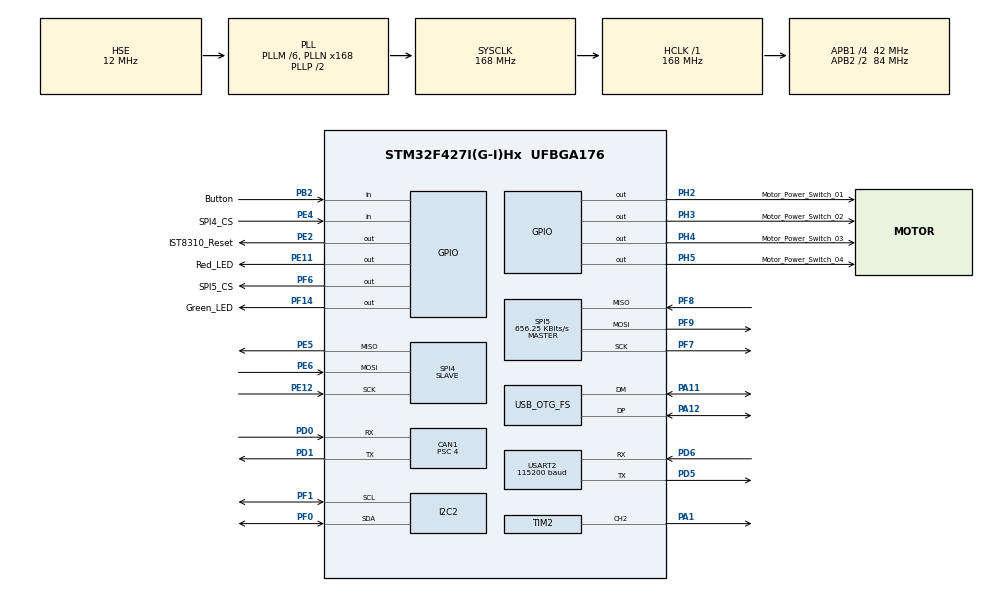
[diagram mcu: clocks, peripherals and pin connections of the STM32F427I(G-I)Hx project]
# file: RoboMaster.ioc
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Mcu.Family=STM32F4
USB_DEVICE.CLASS_NAME_FS=CDC
RCC.CortexFreq_Value=168000000
SPI4.VirtualType=VM_SLAVE
PE11.GPIO_Label=Red_LED
SPI4.Direction=SPI_DIRECTION_2LINES
PA11.Mode=Device_Only
USB_DEVICE.VirtualMode-CDC_FS=Cdc
PH5.GPIO_Label=Motor_Power_Switch_04
TIM2.Channel-PWM\ Generation2\ CH2=TIM_CHANNEL_2
PF6.GPIO_Label=SPI5_CS
RCC.SYSCLKSource=RCC_SYSCLKSOURCE_PLLCLK
ProjectManager.StackSize=0x400
VP_FREERTOS_VS_CMSIS_V2.Mode=CMSIS_V2
PA12.Signal=USB_OTG_FS_DP
PH5.Signal=GPIO_Output
SPI4.Mode=SPI_MODE_SLAVE
PF7.Signal=SPI5_SCK
NVIC.CAN1_TX_IRQn=true\:5\:0\:false\:false\:true\:true\:true\:true
PH0/OSC_IN.Mode=HSE-External-Oscillator
RCC.HCLKFreq_Value=168000000
RCC.APB2TimFreq_Value=168000000
PB2/BOOT1.GPIO_Label=Button
PH1/OSC_OUT.Signal=RCC_OSC_OUT
PD0.Signal=CAN1_RX
PE5.Signal=SPI4_MISO
RCC.AHBFreq_Value=168000000
PD5.Mode=Asynchronous
RCC.HSE_VALUE=12000000
PF9.Mode=Full_Duplex_Master
PE4.GPIO_Label=SPI4_CS
PE2.Signal=GPIO_Output
PF8.Mode=Full_Duplex_Master
PH1/OSC_OUT.Mode=HSE-External-Oscillator
PE4.Signal=GPIO_Input
CAN1.Prescaler=4
Mcu.Package=UFBGA176
SPI5.BaudRatePrescaler=SPI_BAUDRATEPRESCALER_128
TIM2.Prescaler=168
NVIC.TimeBase=TIM8_UP_TIM13_IRQn
USART2.VirtualMode=VM_ASYNC
NVIC.OTG_FS_IRQn=true\:5\:0\:false\:false\:true\:true\:true\:true
NVIC.TimeBaseIP=TIM13
USB_OTG_FS.VirtualMode=Device_Only
PF8.Signal=SPI5_MISO
PH3.GPIO_Label=Motor_Power_Switch_02
SPI5.CalculateBaudRate=656.25 KBits/s
PH2.Signal=GPIO_Output
RCC.APB2CLKDivider=RCC_HCLK_DIV2
PF14.Signal=GPIO_Output
RCC.APB1TimFreq_Value=84000000
PF0.Signal=I2C2_SDA
PD6.Signal=USART2_RX
CAN1.CalculateTimeBit=1142.85
PE2.GPIO_Label=IST8310_Reset
SPI5.VirtualType=VM_MASTER
CAN1.CalculateTimeQuantum=95.23809523809524
PE12.Mode=Full_Duplex_Slave
FREERTOS.Tasks01=DefaultTask,24,1024,StartDefaultTask,Default,NULL,Dynamic,NULL,NULL;BlinkLEDTask,8,128,StartBlinkLEDTask,Default,NULL,Static,myTask02Buffer,myTask02ControlBlock;UpdatePIDTask,32,512,StartUpdatePIDTask,Default,NULL,Static,myTask03Buffer,myTask03ControlBlock;PrintInfo,16,512,StartPrintInfo,Default,NULL,Static,printInfoBuffer,printInfoControlBlock;ActuatorsTask,24,2048,StartActuatorsTask,Default,NULL,Static,ActuatorsTaskBuffer,ActuatorsTaskControlBlock;SensorsTask,24,2048,StartSensorsTask,Default,NULL,Static,SensorsTaskBuffer,SensorsTaskControlBlock;UpdateIMUTask,32,1024,StartUpdateIMUTask,Default,NULL,Static,UpdateIMUTaskBuffer,UpdateIMUTaskControlBlock
USB_DEVICE.VirtualModeFS=Cdc_FS
CAN1.CalculateBaudRate=875000
PD1.Signal=CAN1_TX
PD5.Signal=USART2_TX
PF14.GPIO_Label=Green_LED
RCC.APB1CLKDivider=RCC_HCLK_DIV4
PD6.Mode=Asynchronous
NVIC.USART2_IRQn=true\:5\:0\:false\:false\:true\:true\:true\:true
SPI5.Mode=SPI_MODE_MASTER
USART2.BaudRate=115200
PF7.Mode=Full_Duplex_Master
PF1.Mode=I2C
SH.S_TIM2_CH2.0=TIM2_CH2,PWM Generation2 CH2
PB2/BOOT1.Signal=GPIO_Input
PH4.Signal=GPIO_Output
CAN1.BS2=CAN_BS2_2TQ
PF6.Signal=GPIO_Output
CAN1.BS1=CAN_BS1_9TQ
ProjectManager.TargetToolchain=STM32CubeIDE
VP_USB_DEVICE_VS_USB_DEVICE_CDC_FS.Mode=CDC_FS
PE11.Signal=GPIO_Output
RCC.LSE_VALUE=32768
PA1.Signal=S_TIM2_CH2
CAN1.ABOM=ENABLE
board=custom
RCC.VCOOutputFreq_Value=336000000
PD1.Mode=CAN_Activate
PH4.GPIO_Label=Motor_Power_Switch_03
PH0/OSC_IN.Signal=RCC_OSC_IN
RCC.APB2Freq_Value=84000000
PE6.Mode=Full_Duplex_Slave
VP_SYS_VS_tim13.Mode=TIM13
VP_TIM2_VS_ClockSourceINT.Mode=Internal
PE5.Mode=Full_Duplex_Slave
TIM2.Period=1000
PF1.Signal=I2C2_SCL
PE6.Signal=SPI4_MOSI
Mcu.Name=STM32F427I(G-I)Hx
PD0.Mode=CAN_Activate
PE12.Signal=SPI4_SCK
RCC.48MHZClocksFreq_Value=48000000
RCC.SYSCLKFreq_VALUE=168000000
PA12.Mode=Device_Only
PA11.Signal=USB_OTG_FS_DM
ProjectManager.HeapSize=0x200
PF0.Mode=I2C
PF9.Signal=SPI5_MOSI
RCC.HSI_VALUE=16000000
NVIC.TIM8_UP_TIM13_IRQn=true\:0\:0\:false\:false\:true\:false\:false\:true
RCC.PLLQ=7
NVIC.PriorityGroup=NVIC_PRIORITYGROUP_4
PH3.Signal=GPIO_Output
RCC.PLLM=6
RCC.PLLN=168
TIM2.AutoReloadPreload=TIM_AUTORELOAD_PRELOAD_ENABLE
RCC.APB1Freq_Value=42000000
PH2.GPIO_Label=Motor_Power_Switch_01
NVIC.CAN1_RX0_IRQn=true\:5\:0\:false\:false\:true\:true\:true\:true
SPI5.Direction=SPI_DIRECTION_2LINES

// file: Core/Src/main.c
/* USER CODE BEGIN Header */
/**
  ******************************************************************************
  * @file           : main.c
  * @brief          : Main program body
  ******************************************************************************
  * @attention
  *
  * <h2><center>&copy; Copyright (c) 2021 STMicroelectronics.
  * All rights reserved.</center></h2>
  *
  * This software component is licensed by ST under Ultimate Liberty license
  * SLA0044, the "License"; You may not use this file except in compliance with
  * the License. You may obtain a copy of the License at:
  *                             www.st.com/SLA0044
  *
  ******************************************************************************
  */
/* USER CODE END Header */
#include "main.h"
#include "cmsis_os.h"
#include "usb_device.h"

typedef StaticTask_t osStaticThreadDef_t;

CAN_HandleTypeDef hcan1;

I2C_HandleTypeDef hi2c2;

SPI_HandleTypeDef hspi4;
SPI_HandleTypeDef hspi5;

TIM_HandleTypeDef htim2;

UART_HandleTypeDef huart2;

/* Definitions for DefaultTask */
osThreadId_t DefaultTaskHandle;
const osThreadAttr_t DefaultTask_attributes = {
  .name = "DefaultTask",
  .stack_size = 1024 * 4,
  .priority = (osPriority_t) osPriorityNormal,
};
/* Definitions for BlinkLEDTask */
osThreadId_t BlinkLEDTaskHandle;
uint32_t myTask02Buffer[ 128 ];
osStaticThreadDef_t myTask02ControlBlock;
const osThreadAttr_t BlinkLEDTask_attributes = {
  .name = "BlinkLEDTask",
  .cb_mem = &myTask02ControlBlock,
  .cb_size = sizeof(myTask02ControlBlock),
  .stack_mem = &myTask02Buffer[0],
  .stack_size = sizeof(myTask02Buffer),
  .priority = (osPriority_t) osPriorityLow,
};
/* Definitions for UpdatePIDTask */
osThreadId_t UpdatePIDTaskHandle;
uint32_t myTask03Buffer[ 512 ];
osStaticThreadDef_t myTask03ControlBlock;
const osThreadAttr_t UpdatePIDTask_attributes = {
  .name = "UpdatePIDTask",
  .cb_mem = &myTask03ControlBlock,
  .cb_size = sizeof(myTask03ControlBlock),
  .stack_mem = &myTask03Buffer[0],
  .stack_size = sizeof(myTask03Buffer),
  .priority = (osPriority_t) osPriorityAboveNormal,
};
/* Definitions for PrintInfo */
osThreadId_t PrintInfoHandle;
uint32_t printInfoBuffer[ 512 ];
osStaticThreadDef_t printInfoControlBlock;
const osThreadAttr_t PrintInfo_attributes = {
  .name = "PrintInfo",
  .cb_mem = &printInfoControlBlock,
  .cb_size = sizeof(printInfoControlBlock),
  .stack_mem = &printInfoBuffer[0],
  .stack_size = sizeof(printInfoBuffer),
  .priority = (osPriority_t) osPriorityBelowNormal,
};
/* Definitions for ActuatorsTask */
osThreadId_t ActuatorsTaskHandle;
uint32_t ActuatorsTaskBuffer[ 2048 ];
osStaticThreadDef_t ActuatorsTaskControlBlock;
const osThreadAttr_t ActuatorsTask_attributes = {
  .name = "ActuatorsTask",
  .cb_mem = &ActuatorsTaskControlBlock,
  .cb_size = sizeof(ActuatorsTaskControlBlock),
  .stack_mem = &ActuatorsTaskBuffer[0],
  .stack_size = sizeof(ActuatorsTaskBuffer),
  .priority = (osPriority_t) osPriorityNormal,
};
/* Definitions for SensorsTask */
osThreadId_t SensorsTaskHandle;
uint32_t SensorsTaskBuffer[ 2048 ];
osStaticThreadDef_t SensorsTaskControlBlock;
const osThreadAttr_t SensorsTask_attributes = {
  .name = "SensorsTask",
  .cb_mem = &SensorsTaskControlBlock,
  .cb_size = sizeof(SensorsTaskControlBlock),
  .stack_mem = &SensorsTaskBuffer[0],
  .stack_size = sizeof(SensorsTaskBuffer),
  .priority = (osPriority_t) osPriorityNormal,
};
/* Definitions for UpdateIMUTask */
osThreadId_t UpdateIMUTaskHandle;
uint32_t UpdateIMUTaskBuffer[ 1024 ];
osStaticThreadDef_t UpdateIMUTaskControlBlock;
const osThreadAttr_t UpdateIMUTask_attributes = {
  .name = "UpdateIMUTask",
  .cb_mem = &UpdateIMUTaskControlBlock,
  .cb_size = sizeof(UpdateIMUTaskControlBlock),
  .stack_mem = &UpdateIMUTaskBuffer[0],
  .stack_size = sizeof(UpdateIMUTaskBuffer),
  .priority = (osPriority_t) osPriorityAboveNormal,
};

void SystemClock_Config(void);
static void MX_GPIO_Init(void);
static void MX_USART2_UART_Init(void);
static void MX_CAN1_Init(void);
static void MX_SPI4_Init(void);
static void MX_SPI5_Init(void);
static void MX_I2C2_Init(void);
static void MX_TIM2_Init(void);
void StartDefaultTask(void *argument);
void StartBlinkLEDTask(void *argument);
void StartUpdatePIDTask(void *argument);
void StartPrintInfo(void *argument);
void StartActuatorsTask(void *argument);
void StartSensorsTask(void *argument);
void StartUpdateIMUTask(void *argument);

extern void setup();
extern void defaultLoop();
extern void blinkLEDLoop();
extern void updatePIDLoop();
extern void updateIMULoop();
extern void printInfoLoop();
extern void sensorsLoop();
extern void actuatorsLoop();

/* USER CODE BEGIN 0 */
uint8_t *data = "Hello World from USB CDC\n";
uint8_t buffer[64];
/* USER CODE END 0 */

int main(void)
{

  /* MCU Configuration--------------------------------------------------------*/

  /* Reset of all peripherals, Initializes the Flash interface and the Systick. */
  HAL_Init();

  /* Configure the system clock */
  SystemClock_Config();

  /* Initialize all configured peripherals */
  MX_GPIO_Init();
  MX_USART2_UART_Init();
  MX_CAN1_Init();
  MX_SPI4_Init();
  MX_SPI5_Init();
  MX_I2C2_Init();
  MX_TIM2_Init();

  /* Init scheduler */
  osKernelInitialize();

  /* Create the thread(s) */
  /* creation of DefaultTask */
  DefaultTaskHandle = osThreadNew(StartDefaultTask, NULL, &DefaultTask_attributes);

  /* creation of BlinkLEDTask */
  BlinkLEDTaskHandle = osThreadNew(StartBlinkLEDTask, NULL, &BlinkLEDTask_attributes);

  /* creation of UpdatePIDTask */
  UpdatePIDTaskHandle = osThreadNew(StartUpdatePIDTask, NULL, &UpdatePIDTask_attributes);

  /* creation of PrintInfo */
  PrintInfoHandle = osThreadNew(StartPrintInfo, NULL, &PrintInfo_attributes);

  /* creation of ActuatorsTask */
  ActuatorsTaskHandle = osThreadNew(StartActuatorsTask, NULL, &ActuatorsTask_attributes);

  /* creation of SensorsTask */
  SensorsTaskHandle = osThreadNew(StartSensorsTask, NULL, &SensorsTask_attributes);

  /* creation of UpdateIMUTask */
  UpdateIMUTaskHandle = osThreadNew(StartUpdateIMUTask, NULL, &UpdateIMUTask_attributes);

  /* Start scheduler */
  osKernelStart();

  /* We should never get here as control is now taken by the scheduler */
  /* Infinite loop */
  while (1)
  {
	  CDC_Transmit_FS(data, strlen(data));
	  HAL_Delay (1000);
  }
}

void SystemClock_Config(void)
{
  RCC_OscInitTypeDef RCC_OscInitStruct = {0};
  RCC_ClkInitTypeDef RCC_ClkInitStruct = {0};

  /** Configure the main internal regulator output voltage
  */
  __HAL_RCC_PWR_CLK_ENABLE();
  __HAL_PWR_VOLTAGESCALING_CONFIG(PWR_REGULATOR_VOLTAGE_SCALE1);
  /** Initializes the RCC Oscillators according to the specified parameters
  * in the RCC_OscInitTypeDef structure.
  */
  RCC_OscInitStruct.OscillatorType = RCC_OSCILLATORTYPE_HSE;
  RCC_OscInitStruct.HSEState = RCC_HSE_ON;
  RCC_OscInitStruct.PLL.PLLState = RCC_PLL_ON;
  RCC_OscInitStruct.PLL.PLLSource = RCC_PLLSOURCE_HSE;
  RCC_OscInitStruct.PLL.PLLM = 6;
  RCC_OscInitStruct.PLL.PLLN = 168;
  RCC_OscInitStruct.PLL.PLLP = RCC_PLLP_DIV2;
  RCC_OscInitStruct.PLL.PLLQ = 7;
  if (HAL_RCC_OscConfig(&RCC_OscInitStruct) != HAL_OK)
  {
    Error_Handler();
  }
  /** Initializes the CPU, AHB and APB buses clocks
  */
  RCC_ClkInitStruct.ClockType = RCC_CLOCKTYPE_HCLK|RCC_CLOCKTYPE_SYSCLK
                              |RCC_CLOCKTYPE_PCLK1|RCC_CLOCKTYPE_PCLK2;
  RCC_ClkInitStruct.SYSCLKSource = RCC_SYSCLKSOURCE_PLLCLK;
  RCC_ClkInitStruct.AHBCLKDivider = RCC_SYSCLK_DIV1;
  RCC_ClkInitStruct.APB1CLKDivider = RCC_HCLK_DIV4;
  RCC_ClkInitStruct.APB2CLKDivider = RCC_HCLK_DIV2;

  if (HAL_RCC_ClockConfig(&RCC_ClkInitStruct, FLASH_LATENCY_5) != HAL_OK)
  {
    Error_Handler();
  }
}

static void MX_CAN1_Init(void)
{

  hcan1.Instance = CAN1;
  hcan1.Init.Prescaler = 4;
  hcan1.Init.Mode = CAN_MODE_NORMAL;
  hcan1.Init.SyncJumpWidth = CAN_SJW_1TQ;
  hcan1.Init.TimeSeg1 = CAN_BS1_9TQ;
  hcan1.Init.TimeSeg2 = CAN_BS2_2TQ;
  hcan1.Init.TimeTriggeredMode = DISABLE;
  hcan1.Init.AutoBusOff = ENABLE;
  hcan1.Init.AutoWakeUp = DISABLE;
  hcan1.Init.AutoRetransmission = DISABLE;
  hcan1.Init.ReceiveFifoLocked = DISABLE;
  hcan1.Init.TransmitFifoPriority = DISABLE;
  if (HAL_CAN_Init(&hcan1) != HAL_OK)
  {
    Error_Handler();
  }

}

static void MX_I2C2_Init(void)
{

  hi2c2.Instance = I2C2;
  hi2c2.Init.ClockSpeed = 100000;
  hi2c2.Init.DutyCycle = I2C_DUTYCYCLE_2;
  hi2c2.Init.OwnAddress1 = 0;
  hi2c2.Init.AddressingMode = I2C_ADDRESSINGMODE_7BIT;
  hi2c2.Init.DualAddressMode = I2C_DUALADDRESS_DISABLE;
  hi2c2.Init.OwnAddress2 = 0;
  hi2c2.Init.GeneralCallMode = I2C_GENERALCALL_DISABLE;
  hi2c2.Init.NoStretchMode = I2C_NOSTRETCH_DISABLE;
  if (HAL_I2C_Init(&hi2c2) != HAL_OK)
  {
    Error_Handler();
  }
  /** Configure Analogue filter
  */
  if (HAL_I2CEx_ConfigAnalogFilter(&hi2c2, I2C_ANALOGFILTER_ENABLE) != HAL_OK)
  {
    Error_Handler();
  }
  /** Configure Digital filter
  */
  if (HAL_I2CEx_ConfigDigitalFilter(&hi2c2, 0) != HAL_OK)
  {
    Error_Handler();
  }

}

static void MX_SPI4_Init(void)
{

  /* SPI4 parameter configuration*/
  hspi4.Instance = SPI4;
  hspi4.Init.Mode = SPI_MODE_SLAVE;
  hspi4.Init.Direction = SPI_DIRECTION_2LINES;
  hspi4.Init.DataSize = SPI_DATASIZE_8BIT;
  hspi4.Init.CLKPolarity = SPI_POLARITY_LOW;
  hspi4.Init.CLKPhase = SPI_PHASE_1EDGE;
  hspi4.Init.NSS = SPI_NSS_SOFT;
  hspi4.Init.FirstBit = SPI_FIRSTBIT_MSB;
  hspi4.Init.TIMode = SPI_TIMODE_DISABLE;
  hspi4.Init.CRCCalculation = SPI_CRCCALCULATION_DISABLE;
  hspi4.Init.CRCPolynomial = 10;
  if (HAL_SPI_Init(&hspi4) != HAL_OK)
  {
    Error_Handler();
  }

}

static void MX_SPI5_Init(void)
{

  /* SPI5 parameter configuration*/
  hspi5.Instance = SPI5;
  hspi5.Init.Mode = SPI_MODE_MASTER;
  hspi5.Init.Direction = SPI_DIRECTION_2LINES;
  hspi5.Init.DataSize = SPI_DATASIZE_8BIT;
  hspi5.Init.CLKPolarity = SPI_POLARITY_LOW;
  hspi5.Init.CLKPhase = SPI_PHASE_1EDGE;
  hspi5.Init.NSS = SPI_NSS_SOFT;
  hspi5.Init.BaudRatePrescaler = SPI_BAUDRATEPRESCALER_128;
  hspi5.Init.FirstBit = SPI_FIRSTBIT_MSB;
  hspi5.Init.TIMode = SPI_TIMODE_DISABLE;
  hspi5.Init.CRCCalculation = SPI_CRCCALCULATION_DISABLE;
  hspi5.Init.CRCPolynomial = 10;
  if (HAL_SPI_Init(&hspi5) != HAL_OK)
  {
    Error_Handler();
  }

}

static void MX_TIM2_Init(void)
{

  TIM_ClockConfigTypeDef sClockSourceConfig = {0};
  TIM_MasterConfigTypeDef sMasterConfig = {0};
  TIM_OC_InitTypeDef sConfigOC = {0};

  htim2.Instance = TIM2;
  htim2.Init.Prescaler = 168;
  htim2.Init.CounterMode = TIM_COUNTERMODE_UP;
  htim2.Init.Period = 1000;
  htim2.Init.ClockDivision = TIM_CLOCKDIVISION_DIV1;
  htim2.Init.AutoReloadPreload = TIM_AUTORELOAD_PRELOAD_ENABLE;
  if (HAL_TIM_Base_Init(&htim2) != HAL_OK)
  {
    Error_Handler();
  }
  sClockSourceConfig.ClockSource = TIM_CLOCKSOURCE_INTERNAL;
  if (HAL_TIM_ConfigClockSource(&htim2, &sClockSourceConfig) != HAL_OK)
  {
    Error_Handler();
  }
  if (HAL_TIM_PWM_Init(&htim2) != HAL_OK)
  {
    Error_Handler();
  }
  sMasterConfig.MasterOutputTrigger = TIM_TRGO_RESET;
  sMasterConfig.MasterSlaveMode = TIM_MASTERSLAVEMODE_DISABLE;
  if (HAL_TIMEx_MasterConfigSynchronization(&htim2, &sMasterConfig) != HAL_OK)
  {
    Error_Handler();
  }
  sConfigOC.OCMode = TIM_OCMODE_PWM1;
  sConfigOC.Pulse = 0;
  sConfigOC.OCPolarity = TIM_OCPOLARITY_HIGH;
  sConfigOC.OCFastMode = TIM_OCFAST_DISABLE;
  if (HAL_TIM_PWM_ConfigChannel(&htim2, &sConfigOC, TIM_CHANNEL_2) != HAL_OK)
  {
    Error_Handler();
  }
  HAL_TIM_MspPostInit(&htim2);

}

static void MX_USART2_UART_Init(void)
{

  huart2.Instance = USART2;
  huart2.Init.BaudRate = 115200;
  huart2.Init.WordLength = UART_WORDLENGTH_8B;
  huart2.Init.StopBits = UART_STOPBITS_1;
  huart2.Init.Parity = UART_PARITY_NONE;
  huart2.Init.Mode = UART_MODE_TX_RX;
  huart2.Init.HwFlowCtl = UART_HWCONTROL_NONE;
  huart2.Init.OverSampling = UART_OVERSAMPLING_16;
  if (HAL_UART_Init(&huart2) != HAL_OK)
  {
    Error_Handler();
  }

}

static void MX_GPIO_Init(void)
{
  GPIO_InitTypeDef GPIO_InitStruct = {0};

  /* GPIO Ports Clock Enable */
  __HAL_RCC_GPIOE_CLK_ENABLE();
  __HAL_RCC_GPIOD_CLK_ENABLE();
  __HAL_RCC_GPIOA_CLK_ENABLE();
  __HAL_RCC_GPIOF_CLK_ENABLE();
  __HAL_RCC_GPIOH_CLK_ENABLE();
  __HAL_RCC_GPIOB_CLK_ENABLE();

  /*Configure GPIO pin Output Level */
  HAL_GPIO_WritePin(GPIOE, IST8310_Reset_Pin|Red_LED_Pin, GPIO_PIN_RESET);

  /*Configure GPIO pin Output Level */
  HAL_GPIO_WritePin(GPIOH, Motor_Power_Switch_01_Pin|Motor_Power_Switch_02_Pin|Motor_Power_Switch_03_Pin|Motor_Power_Switch_04_Pin, GPIO_PIN_RESET);

  /*Configure GPIO pin Output Level */
  HAL_GPIO_WritePin(GPIOF, SPI5_CS_Pin|Green_LED_Pin, GPIO_PIN_RESET);

  /*Configure GPIO pins : IST8310_Reset_Pin Red_LED_Pin */
  GPIO_InitStruct.Pin = IST8310_Reset_Pin|Red_LED_Pin;
  GPIO_InitStruct.Mode = GPIO_MODE_OUTPUT_PP;
  GPIO_InitStruct.Pull = GPIO_NOPULL;
  GPIO_InitStruct.Speed = GPIO_SPEED_FREQ_LOW;
  HAL_GPIO_Init(GPIOE, &GPIO_InitStruct);

  /*Configure GPIO pin : SPI4_CS_Pin */
  GPIO_InitStruct.Pin = SPI4_CS_Pin;
  GPIO_InitStruct.Mode = GPIO_MODE_INPUT;
  GPIO_InitStruct.Pull = GPIO_NOPULL;
  HAL_GPIO_Init(SPI4_CS_GPIO_Port, &GPIO_InitStruct);

  /*Configure GPIO pins : Motor_Power_Switch_01_Pin Motor_Power_Switch_02_Pin Motor_Power_Switch_03_Pin Motor_Power_Switch_04_Pin */
  GPIO_InitStruct.Pin = Motor_Power_Switch_01_Pin|Motor_Power_Switch_02_Pin|Motor_Power_Switch_03_Pin|Motor_Power_Switch_04_Pin;
  GPIO_InitStruct.Mode = GPIO_MODE_OUTPUT_PP;
  GPIO_InitStruct.Pull = GPIO_NOPULL;
  GPIO_InitStruct.Speed = GPIO_SPEED_FREQ_LOW;
  HAL_GPIO_Init(GPIOH, &GPIO_InitStruct);

  /*Configure GPIO pins : SPI5_CS_Pin Green_LED_Pin */
  GPIO_InitStruct.Pin = SPI5_CS_Pin|Green_LED_Pin;
  GPIO_InitStruct.Mode = GPIO_MODE_OUTPUT_PP;
  GPIO_InitStruct.Pull = GPIO_NOPULL;
  GPIO_InitStruct.Speed = GPIO_SPEED_FREQ_LOW;
  HAL_GPIO_Init(GPIOF, &GPIO_InitStruct);

  /*Configure GPIO pin : Button_Pin */
  GPIO_InitStruct.Pin = Button_Pin;
  GPIO_InitStruct.Mode = GPIO_MODE_INPUT;
  GPIO_InitStruct.Pull = GPIO_NOPULL;
  HAL_GPIO_Init(Button_GPIO_Port, &GPIO_InitStruct);

}

void StartDefaultTask(void *argument)
{
  /* init code for USB_DEVICE */
  MX_USB_DEVICE_Init();
  /* USER CODE BEGIN 5 */
  setup();
  /* Infinite loop */
  for(;;)
  {
	defaultLoop();
    osDelay(1);
  }
  /* USER CODE END 5 */
}

void StartBlinkLEDTask(void *argument)
{
  /* USER CODE BEGIN StartBlinkLEDTask */
  /* Infinite loop */
  for(;;)
  {
	blinkLEDLoop();
    osDelay(1);
  }
  /* USER CODE END StartBlinkLEDTask */
}

void StartUpdatePIDTask(void *argument)
{
  /* USER CODE BEGIN StartUpdatePIDTask */
  /* Infinite loop */
  for(;;)
  {
	updatePIDLoop();
    osDelay(1);
  }
  /* USER CODE END StartUpdatePIDTask */
}

void StartPrintInfo(void *argument)
{
  /* USER CODE BEGIN StartPrintInfo */
  /* Infinite loop */
  for(;;)
  {
	printInfoLoop();
    osDelay(1);
  }
  /* USER CODE END StartPrintInfo */
}

void StartActuatorsTask(void *argument)
{
  /* USER CODE BEGIN StartActuatorsTask */
  /* Infinite loop */
  for(;;)
  {
	actuatorsLoop();
    osDelay(1);
  }
  /* USER CODE END StartActuatorsTask */
}

void StartSensorsTask(void *argument)
{
  /* USER CODE BEGIN StartSensorsTask */
  /* Infinite loop */
  for(;;)
  {
	sensorsLoop();
    osDelay(1);
  }
  /* USER CODE END StartSensorsTask */
}

void StartUpdateIMUTask(void *argument)
{
  /* USER CODE BEGIN StartUpdateIMUTask */
  /* Infinite loop */
  for(;;)
  {
	updateIMULoop();
    osDelay(1);
  }
  /* USER CODE END StartUpdateIMUTask */
}

 /**
  * @brief  Period elapsed callback in non blocking mode
  * @note   This function is called  when TIM13 interrupt took place, inside
  * HAL_TIM_IRQHandler(). It makes a direct call to HAL_IncTick() to increment
  * a global variable "uwTick" used as application time base.
  * @param  htim : TIM handle
  * @retval None
  */
void HAL_TIM_PeriodElapsedCallback(TIM_HandleTypeDef *htim)
{
  if (htim->Instance == TIM13) {
    HAL_IncTick();
  }
}

void Error_Handler(void)
{
  __disable_irq();
  while (1)
  {
  }
}

/************************ (C) COPYRIGHT STMicroelectronics *****END OF FILE****/
